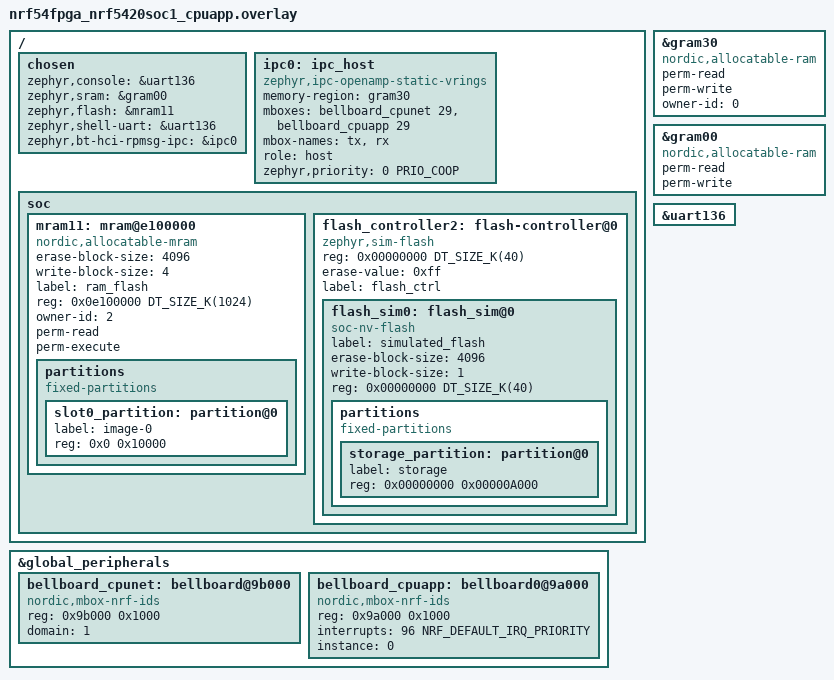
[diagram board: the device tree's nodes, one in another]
/*
 * Copyright (c) 2022 Nordic Semiconductor ASA
 *
 * SPDX-License-Identifier: Apache-2.0
 */

#include <zephyr/dt-bindings/ipc_service/static_vrings.h>


/*
 * Chosen dts configs description:
 * - Console and shell-uart connected to the uart-bellboard to get output on server.
 * - SRAM set to gram00 due to its big size and speed.
 * - - Current flash layout does not allow the application domain to use both mram10 and mram11 in one continuous block. mram11 is selected due to its available size.
 * - IPC0 is used to connect Appcore and Netcore - it MUST be set to the same value in NetCore dts.
 * - flash_controller2 is defined to allow using RAM as a FLASH simulator - it is required to store Zephyr's settings in RAM.
 */

/ {
    chosen {
        zephyr,console = &uart136;
        zephyr,sram = &gram00;
        zephyr,flash = &mram11;
        zephyr,shell-uart = &uart136;
        zephyr,bt-hci-rpmsg-ipc = &ipc0;
    };
    ipc0: ipc_host {
        compatible = "zephyr,ipc-openamp-static-vrings";
        memory-region = <&gram30>;
        mboxes = <&bellboard_cpunet 29>,
             <&bellboard_cpuapp 29>;
        mbox-names = "tx", "rx";
        role = "host";
        status = "okay";
        zephyr,priority = <0 PRIO_COOP>;
    };
};

&gram30 {
    compatible = "nordic,allocatable-ram";
    perm-read;
    perm-write;
    owner-id = <0>;
};

&gram00 {
    compatible = "nordic,allocatable-ram";
    perm-read;
    perm-write;
};

&ipc0 {
    zephyr,priority = <0 PRIO_COOP>;
};

&uart136 {
	status = "okay";
};

&global_peripherals {
    /delete-node/ bellboard@9a000;
    /delete-node/ bellboard@9b000;
    bellboard_cpunet: bellboard@9b000 {
        compatible = "nordic,mbox-nrf-ids";
        reg = <0x9b000 0x1000>;
        domain = <1>;
        status = "okay";
        #mbox-cells = <1>;
    };
    bellboard_cpuapp: bellboard0@9a000 {
        compatible = "nordic,mbox-nrf-ids";
        reg = <0x9a000 0x1000>;
        interrupts = <96 NRF_DEFAULT_IRQ_PRIORITY>;
        instance = <0>;
        status = "okay";
        #mbox-cells = <1>;
    };
};


/delete-node/ &slot0_partition;

/ {
	soc {
		mram11: mram@e100000 {
			compatible = "nordic,allocatable-mram";
			erase-block-size = <4096>;
			write-block-size = <4>;
            label = "ram_flash";
			reg = <0x0e100000 DT_SIZE_K(1024)>;
            owner-id = <2>;
            perm-read; 
            perm-execute;
            partitions {
				compatible = "fixed-partitions";
				#address-cells = < 0x1 >;
				#size-cells = < 0x1 >;
				slot0_partition: partition@0 {
					label = "image-0";
					reg = < 0x0 0x10000 >;
				};
			};
		};
	};
};

/ {
	soc {
		flash_controller2: flash-controller@0 {
			compatible = "zephyr,sim-flash";
			reg = <0x00000000 DT_SIZE_K(40)>;

			#address-cells = <1>;
			#size-cells = <1>;
			erase-value = <0xff>;

			label = "flash_ctrl";

			flash_sim0: flash_sim@0 {
				status = "okay";
				compatible = "soc-nv-flash";
				label = "simulated_flash";
				erase-block-size = <4096>;
				write-block-size = <1>;
				reg = <0x00000000 DT_SIZE_K(40)>;

				partitions {
					compatible = "fixed-partitions";
					#address-cells = <1>;
					#size-cells = <1>;

					storage_partition: partition@0 {
						label = "storage";
						reg = <0x00000000 0x00000A000>;
					};
				};
			};
		};
	};
};
